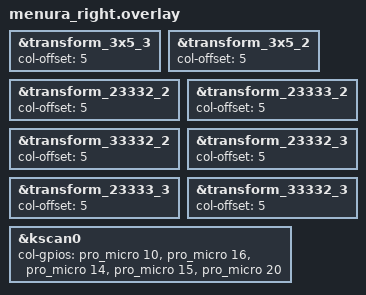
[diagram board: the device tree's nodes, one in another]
#include "menura.dtsi"

&transform_3x5_3{
    col-offset = <5>;
};

&transform_3x5_2{
    col-offset = <5>;
};

&transform_23332_2{
    col-offset = <5>;
};

&transform_23333_2{
    col-offset = <5>;
};

&transform_33332_2{
    col-offset = <5>;
};

&transform_23332_3{
    col-offset = <5>;
};

&transform_23333_3{
    col-offset = <5>;
};

&transform_33332_3{
    col-offset = <5>;
};

&kscan0 {
    col-gpios
        = <&pro_micro 10 GPIO_ACTIVE_HIGH>
        , <&pro_micro 16 GPIO_ACTIVE_HIGH>
        , <&pro_micro 14 GPIO_ACTIVE_HIGH>
        , <&pro_micro 15 GPIO_ACTIVE_HIGH>
        , <&pro_micro 20 GPIO_ACTIVE_HIGH>
        ;
};
